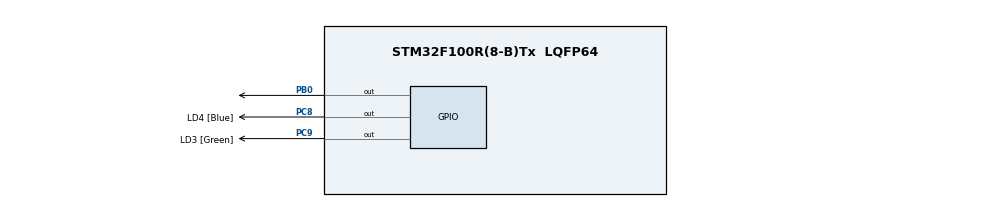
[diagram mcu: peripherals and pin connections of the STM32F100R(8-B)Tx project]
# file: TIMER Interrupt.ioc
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Mcu.Family=STM32F1
Mcu.Name=STM32F100R(8-B)Tx
Mcu.Package=LQFP64
NVIC.PriorityGroup=NVIC_PRIORITYGROUP_4
NVIC.TIM1_BRK_TIM15_IRQn=true\:0\:0\:false\:false\:true\:true\:true
NVIC.TIM1_UP_TIM16_IRQn=true\:0\:0\:false\:false\:true\:true\:true
PA0-WKUP.Mode=SYS_WakeUp0
PA0-WKUP.Signal=SYS_WKUP
PA13.GPIO_Label=TMS_SWDIO
PA13.Mode=Serial_Wire
PA13.Signal=SYS_JTMS-SWDIO
PA14.GPIO_Label=TCK_SWCLK
PA14.Mode=Serial_Wire
PA14.Signal=SYS_JTCK-SWCLK
PB0.GPIO_Speed=GPIO_SPEED_FREQ_HIGH
PB0.Signal=GPIO_Output
PC14-OSC32_IN.Mode=LSE-External-Oscillator
PC14-OSC32_IN.Signal=RCC_OSC32_IN
PC15-OSC32_OUT.Mode=LSE-External-Oscillator
PC15-OSC32_OUT.Signal=RCC_OSC32_OUT
PC8.GPIO_Label=LD4 [Blue]
PC8.Signal=GPIO_Output
PC9.GPIO_Label=LD3 [Green]
PC9.Signal=GPIO_Output
PD0-OSC_IN.Mode=HSE-External-Oscillator
PD0-OSC_IN.Signal=RCC_OSC_IN
PD1-OSC_OUT.Mode=HSE-External-Oscillator
PD1-OSC_OUT.Signal=RCC_OSC_OUT
ProjectManager.HeapSize=0x200
ProjectManager.StackSize=0x400
ProjectManager.TargetToolchain=MDK-ARM V5.27
RCC.APB1Freq_Value=8000000
RCC.APB2Freq_Value=8000000
TIM1.Period=1999
TIM1.Prescaler=3999
VP_TIM1_VS_ClockSourceINT.Mode=Internal
board=STM32VLDISCOVERY

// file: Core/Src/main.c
/* USER CODE BEGIN Header */
/**
  ******************************************************************************
  * @file           : main.c
  * @brief          : Main program body
  ******************************************************************************
  * @attention
  *
  * Copyright (c) 2022 STMicroelectronics.
  * All rights reserved.
  *
  * This software is licensed under terms that can be found in the LICENSE file
  * in the root directory of this software component.
  * If no LICENSE file comes with this software, it is provided AS-IS.
  *
  ******************************************************************************
  */
/* USER CODE END Header */
#include "main.h"

TIM_HandleTypeDef htim1;

void SystemClock_Config(void);
static void MX_GPIO_Init(void);
static void MX_TIM1_Init(void);

int main(void)
{

  /* MCU Configuration--------------------------------------------------------*/

  /* Reset of all peripherals, Initializes the Flash interface and the Systick. */
  HAL_Init();

  /* Configure the system clock */
  SystemClock_Config();

  /* Initialize all configured peripherals */
  MX_GPIO_Init();
  MX_TIM1_Init();
  /* USER CODE BEGIN 2 */
	HAL_TIM_Base_Start_IT(&htim1);
  /* USER CODE END 2 */

  /* Infinite loop */
  while (1)
  {

  }
}

void SystemClock_Config(void)
{
  RCC_OscInitTypeDef RCC_OscInitStruct = {0};
  RCC_ClkInitTypeDef RCC_ClkInitStruct = {0};

  /** Initializes the RCC Oscillators according to the specified parameters
  * in the RCC_OscInitTypeDef structure.
  */
  RCC_OscInitStruct.OscillatorType = RCC_OSCILLATORTYPE_HSI;
  RCC_OscInitStruct.HSIState = RCC_HSI_ON;
  RCC_OscInitStruct.HSICalibrationValue = RCC_HSICALIBRATION_DEFAULT;
  RCC_OscInitStruct.PLL.PLLState = RCC_PLL_NONE;
  if (HAL_RCC_OscConfig(&RCC_OscInitStruct) != HAL_OK)
  {
    Error_Handler();
  }
  /** Initializes the CPU, AHB and APB buses clocks
  */
  RCC_ClkInitStruct.ClockType = RCC_CLOCKTYPE_HCLK|RCC_CLOCKTYPE_SYSCLK
                              |RCC_CLOCKTYPE_PCLK1|RCC_CLOCKTYPE_PCLK2;
  RCC_ClkInitStruct.SYSCLKSource = RCC_SYSCLKSOURCE_HSI;
  RCC_ClkInitStruct.AHBCLKDivider = RCC_SYSCLK_DIV1;
  RCC_ClkInitStruct.APB1CLKDivider = RCC_HCLK_DIV1;
  RCC_ClkInitStruct.APB2CLKDivider = RCC_HCLK_DIV1;

  if (HAL_RCC_ClockConfig(&RCC_ClkInitStruct, FLASH_LATENCY_0) != HAL_OK)
  {
    Error_Handler();
  }
}

static void MX_TIM1_Init(void)
{

  TIM_ClockConfigTypeDef sClockSourceConfig = {0};
  TIM_MasterConfigTypeDef sMasterConfig = {0};

  htim1.Instance = TIM1;
  htim1.Init.Prescaler = 3999;
  htim1.Init.CounterMode = TIM_COUNTERMODE_UP;
  htim1.Init.Period = 1999;
  htim1.Init.ClockDivision = TIM_CLOCKDIVISION_DIV1;
  htim1.Init.RepetitionCounter = 0;
  htim1.Init.AutoReloadPreload = TIM_AUTORELOAD_PRELOAD_DISABLE;
  if (HAL_TIM_Base_Init(&htim1) != HAL_OK)
  {
    Error_Handler();
  }
  sClockSourceConfig.ClockSource = TIM_CLOCKSOURCE_INTERNAL;
  if (HAL_TIM_ConfigClockSource(&htim1, &sClockSourceConfig) != HAL_OK)
  {
    Error_Handler();
  }
  sMasterConfig.MasterOutputTrigger = TIM_TRGO_RESET;
  sMasterConfig.MasterSlaveMode = TIM_MASTERSLAVEMODE_DISABLE;
  if (HAL_TIMEx_MasterConfigSynchronization(&htim1, &sMasterConfig) != HAL_OK)
  {
    Error_Handler();
  }

}

static void MX_GPIO_Init(void)
{
  GPIO_InitTypeDef GPIO_InitStruct = {0};

  /* GPIO Ports Clock Enable */
  __HAL_RCC_GPIOC_CLK_ENABLE();
  __HAL_RCC_GPIOD_CLK_ENABLE();
  __HAL_RCC_GPIOA_CLK_ENABLE();
  __HAL_RCC_GPIOB_CLK_ENABLE();

  /*Configure GPIO pin Output Level */
  HAL_GPIO_WritePin(GPIOB, GPIO_PIN_0, GPIO_PIN_RESET);

  /*Configure GPIO pin Output Level */
  HAL_GPIO_WritePin(GPIOC, LD4_Pin|LD3_Pin, GPIO_PIN_RESET);

  /*Configure GPIO pin : PB0 */
  GPIO_InitStruct.Pin = GPIO_PIN_0;
  GPIO_InitStruct.Mode = GPIO_MODE_OUTPUT_PP;
  GPIO_InitStruct.Pull = GPIO_NOPULL;
  GPIO_InitStruct.Speed = GPIO_SPEED_FREQ_HIGH;
  HAL_GPIO_Init(GPIOB, &GPIO_InitStruct);

  /*Configure GPIO pins : LD4_Pin LD3_Pin */
  GPIO_InitStruct.Pin = LD4_Pin|LD3_Pin;
  GPIO_InitStruct.Mode = GPIO_MODE_OUTPUT_PP;
  GPIO_InitStruct.Pull = GPIO_NOPULL;
  GPIO_InitStruct.Speed = GPIO_SPEED_FREQ_LOW;
  HAL_GPIO_Init(GPIOC, &GPIO_InitStruct);

}

/* USER CODE BEGIN 4 */
void HAL_TIM_PeriodElapsedCallback(TIM_HandleTypeDef *htim)
{
  HAL_GPIO_TogglePin(GPIOB,GPIO_PIN_0);
}
/* USER CODE END 4 */

void Error_Handler(void)
{
  __disable_irq();
  while (1)
  {
  }
}
